# EFR32FG22C121F512GM32 register map
Vendor: Silicon Labs; Series: EFR32; File version: C
Registers are 32-bit, read-write, reset 0x0 unless marked. A register's access mark holds for its fields unless they carry their own. Offsets are from the block's base; [hi:lo] are bit positions; {n}, {i} and the like mark numbered series; 'fields as' and 'values as' point back to an identical list.

## CMU_S — CMU_S Registers
Base 0x40008000
Same registers: CMU_NS 0x50008000
0x00 IPVERSION ro reset 0x1
  [31:0] IPVERSION — IP Version ID
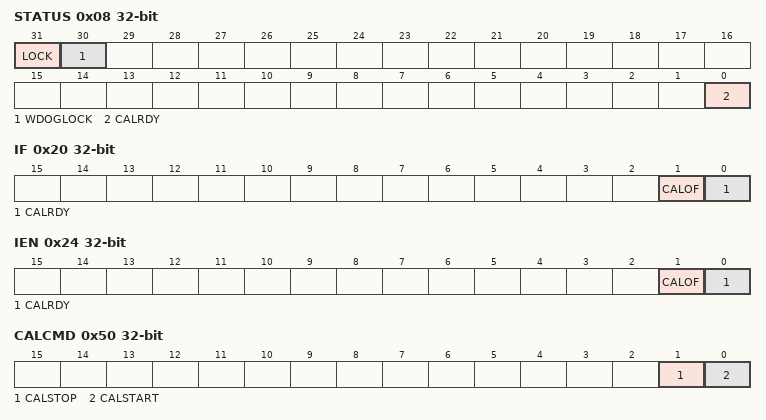
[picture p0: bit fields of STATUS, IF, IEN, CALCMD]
0x08 STATUS ro
  [31] LOCK — Configuration Lock Status
    0=UNLOCKED (Configuration lock is unlocked); 1=LOCKED (Configuration lock is locked)
  [30] WDOGLOCK — Configuration Lock Status for WDOG
    0=UNLOCKED (WDOG configuration lock is unlocked); 1=LOCKED (WDOG configuration lock is locked)
  [0] CALRDY — Calibration Ready
0x10 LOCK wo reset 0x93F7
  [15:0] LOCKKEY — Configuration Lock Key
    0x93F7=UNLOCK (Write this value to unlock)
0x14 WDOGLOCK wo reset 0x5257
  fields as LOCK
0x20 IF
  [1] CALOF — Calibration Overflow Interrupt Flag
  [0] CALRDY — Calibration Ready Interrupt Flag
0x24 IEN
  [1] CALOF — Calibration Overflow Interrupt Enable
  [0] CALRDY — Calibration Ready Interrupt Enable
0x50 CALCMD wo
  [1] CALSTOP — Calibration Stop
  [0] CALSTART — Calibration Start
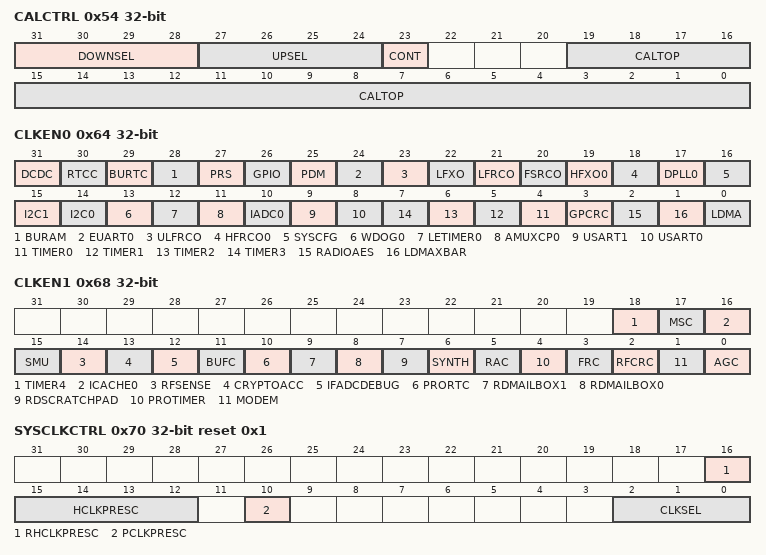
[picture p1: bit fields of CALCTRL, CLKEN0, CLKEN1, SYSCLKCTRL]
0x54 CALCTRL
  [31:28] DOWNSEL — Calibration Down-counter Select
    0=DISABLED (Down-counter is not clocked); 1=HCLK (HCLK is clocking down-counter); 2=PRS (PRS CMU_CALDN consumer is clocking down-counter); 3=HFXO (HFXO is clocking down-counter); 4=LFXO (LFXO is clocking down-counter); 5=HFRCODPLL (HFRCODPLL is clocking down-counter); 9=FSRCO (FSRCO is clocking down-counter); 10=LFRCO (LFRCO is clocking down-counter); 11=ULFRCO (ULFRCO is clocking down-counter)
  [27:24] UPSEL — Calibration Up-counter Select
    0=DISABLED (Up-counter is not clocked); 1=PRS (PRS CMU_CALUP consumer is clocking up-counter); 2=HFXO (HFXO is clocking up-counter); 3=LFXO (LFXO is clocking up-counter); 4=HFRCODPLL (HFRCODPLL is clocking up-counter); 8=FSRCO (FSRCO is clocking up-counter); 9=LFRCO (LFRCO is clocking up-counter); 10=ULFRCO (ULFRCO is clocking up-counter)
  [23] CONT — Continuous Calibration
  [19:0] CALTOP — Calibration Counter Top Value
0x58 CALCNT ro
  [19:0] CALCNT — Calibration Result Counter Value
0x64 CLKEN0
  [31] DCDC — Enable Bus Clock
  [30] RTCC — Enable Bus Clock
  [29] BURTC — Enable Bus Clock
  [28] BURAM — Enable Bus Clock
  [27] PRS — Enable Bus Clock
  [26] GPIO — Enable Bus Clock
  [25] PDM — Enable Bus Clock
  [24] EUART0 — Enable Bus Clock
  [23] ULFRCO — Enable Bus Clock
  [22] LFXO — Enable Bus Clock
  [21] LFRCO — Enable Bus Clock
  [20] FSRCO — Enable Bus Clock
  [19] HFXO0 — Enable Bus Clock
  [18] HFRCO0 — Enable Bus Clock
  [17] DPLL0 — Enable Bus Clock
  [16] SYSCFG — Enable Bus Clock
  [15] I2C1 — Enable Bus Clock
  [14] I2C0 — Enable Bus Clock
  [13] WDOG0 — Enable Bus Clock
  [12] LETIMER0 — Enable Bus Clock
  [11] AMUXCP0 — Enable Bus Clock
  [10] IADC0 — Enable Bus Clock
  [9] USART1 — Enable Bus Clock
  [8] USART0 — Enable Bus Clock
  [n+4] TIMER{n} (n=0..3) — Enable Bus Clock
  [3] GPCRC — Enable Bus Clock
  [2] RADIOAES — Enable Bus Clock
  [1] LDMAXBAR — Enable Bus Clock
  [0] LDMA — Enable Bus Clock
0x68 CLKEN1
  [18] TIMER4 — Enable Bus Clock
  [17] MSC — Enable Bus Clock
  [16] ICACHE0 — Enable Bus Clock
  [15] SMU — Enable Bus Clock
  [14] RFSENSE — Enable Bus Clock
  [13] CRYPTOACC — Enable Bus Clock
  [12] IFADCDEBUG — Enable Bus Clock
  [11] BUFC — Enable Bus Clock
  [10] PRORTC — Enable Bus Clock
  [9] RDMAILBOX1 — Enable Bus Clock
  [8] RDMAILBOX0 — Enable Bus Clock
  [7] RDSCRATCHPAD — Enable Bus Clock
  [6] SYNTH — Enable Bus Clock
  [5] RAC — Enable Bus Clock
  [4] PROTIMER — Enable Bus Clock
  [3] FRC — Enable Bus Clock
  [2] RFCRC — Enable Bus Clock
  [1] MODEM — Enable Bus Clock
  [0] AGC — Enable Bus Clock
0x70 SYSCLKCTRL reset 0x1
  [16] RHCLKPRESC — Radio HCLK Prescaler
    0=DIV1 (Radio HCLK is SYSCLK divided by 1); 1=DIV2 (Radio HCLK is SYSCLK divided by 2)
  [15:12] HCLKPRESC — HCLK Prescaler
    0=DIV1 (HCLK is SYSCLK divided by 1); 1=DIV2 (HCLK is SYSCLK divided by 2); 3=DIV4 (HCLK is SYSCLK divided by 4); 7=DIV8 (HCLK is SYSCLK divided by 8); 15=DIV16 (HCLK is SYSCLK divided by 16)
  [10] PCLKPRESC — PCLK Prescaler
    0=DIV1 (PCLK is HCLK divided by 1); 1=DIV2 (PCLK is HCLK divided by 2)
  [2:0] CLKSEL — Clock Select
    1=FSRCO (FSRCO is clocking SYSCLK); 2=HFRCODPLL (HFRCODPLL is clocking SYSCLK); 3=HFXO (HFXO is clocking SYSCLK); 4=CLKIN0 (CLKIN0 is clocking SYSCLK)
0x80 TRACECLKCTRL
  [5:4] PRESC — TRACECLK Prescaler
    0=DIV1 (TRACECLK is SYSCLK divided by 1); 1=DIV2 (TRACECLK is SYSCLK divided by 2); 3=DIV4 (TRACECLK is SYSCLK divided by 4)
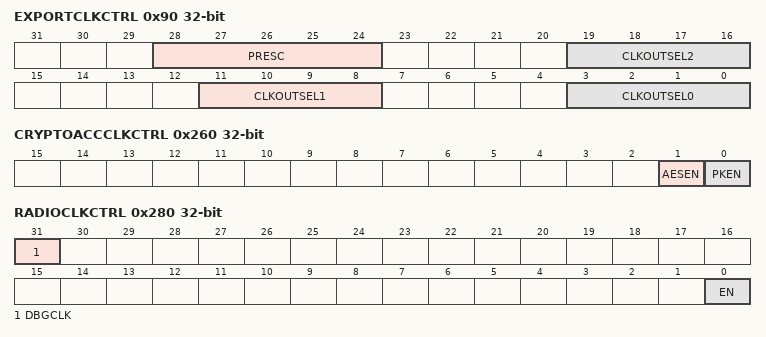
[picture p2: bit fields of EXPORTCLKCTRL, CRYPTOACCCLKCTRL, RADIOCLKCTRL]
0x90 EXPORTCLKCTRL
  [28:24] PRESC — EXPORTCLK Prescaler
  [19:16] CLKOUTSEL2 — Clock Output Select 2
    0=DISABLED (CLKOUT2 is not clocked); 1=HCLK (HCLK is clocking CLKOUT2); 2=HFEXPCLK (EXPORTCLK is clocking CLKOUT2); 3=ULFRCO (ULFRCO is clocking CLKOUT2); 4=LFRCO (LFRCO is clocking CLKOUT2); 5=LFXO (LFXO is clocking CLKOUT2); 6=HFRCODPLL (HFRCODPLL is clocking CLKOUT2); 7=HFXO (HFXO is clocking CLKOUT2); 8=FSRCO (FSRCO is clocking CLKOUT2)
  [11:8] CLKOUTSEL1 — Clock Output Select 1
    0=DISABLED (CLKOUT1 is not clocked); 1=HCLK (HCLK is clocking CLKOUT1); 2=HFEXPCLK (EXPORTCLK is clocking CLKOUT1); 3=ULFRCO (ULFRCO is clocking CLKOUT1); 4=LFRCO (LFRCO is clocking CLKOUT1); 5=LFXO (LFXO is clocking CLKOUT1); 6=HFRCODPLL (HFRCODPLL is clocking CLKOUT1); 7=HFXO (HFXO is clocking CLKOUT1); 8=FSRCO (FSRCO is clocking CLKOUT1)
  [3:0] CLKOUTSEL0 — Clock Output Select 0
    0=DISABLED (CLKOUT0 is not clocked); 1=HCLK (HCLK is clocking CLKOUT0); 2=HFEXPCLK (EXPORTCLK is clocking CLKOUT0); 3=ULFRCO (ULFRCO is clocking CLKOUT0); 4=LFRCO (LFRCO is clocking CLKOUT0); 5=LFXO (LFXO is clocking CLKOUT0); 6=HFRCODPLL (HFRCODPLL is clocking CLKOUT0); 7=HFXO (HFXO is clocking CLKOUT0); 8=FSRCO (FSRCO is clocking CLKOUT0)
0x100 DPLLREFCLKCTRL
  [1:0] CLKSEL — Clock Select
    0=DISABLED (DPLLREFCLK is not clocked); 1=HFXO (HFXO is clocking DPLLREFCLK); 2=LFXO (LFXO is clocking DPLLREFCLK); 3=CLKIN0 (CLKIN0 is clocking DPLLREFCLK)
0x120 EM01GRPACLKCTRL reset 0x1
  [1:0] CLKSEL — Clock Select
    1=HFRCODPLL (HFRCODPLL is clocking EM01GRPACLK); 2=HFXO (HFXO is clocking EM01GRPACLK); 3=FSRCO (FSRCO is clocking EM01GRPACLK)
0x124 EM01GRPBCLKCTRL reset 0x1
  [2:0] CLKSEL — Clock Select
    1=HFRCODPLL (HFRCODPLL is clocking EM01GRPBCLK); 2=HFXO (HFXO is clocking EM01GRPBCLK); 3=FSRCO (FSRCO is clocking EM01GRPBCLK); 4=CLKIN0 (CLKIN0 is clocking EM01GRPBCLK); 5=HFRCODPLLRT (HFRCODPLL (re-timed) is clocking EM01GRPBCLK); 6=HFXORT (HFXO (re-timed) is clocking EM01GRPBCLK)
0x140 EM23GRPACLKCTRL reset 0x1
  [1:0] CLKSEL — Clock Select
    1=LFRCO (LFRCO is clocking EM23GRPACLK); 2=LFXO (LFXO is clocking EM23GRPACLK); 3=ULFRCO (ULFRCO is clocking EM23GRPACLK)
0x160 EM4GRPACLKCTRL reset 0x1
  [1:0] CLKSEL — Clock Select
    1=LFRCO (LFRCO is clocking EM4GRPACLK); 2=LFXO (LFXO is clocking EM4GRPACLK); 3=ULFRCO (ULFRCO is clocking EM4GRPACLK)
0x180 IADCCLKCTRL reset 0x1
  [1:0] CLKSEL — Clock Select
    1=EM01GRPACLK (EM01GRPACLK is clocking IADCCLK); 2=FSRCO (FSRCO is clocking IADCCLK)
0x200 WDOG0CLKCTRL reset 0x1
  [2:0] CLKSEL — Clock Select
    1=LFRCO (LFRCO is clocking WDOG0CLK); 2=LFXO (LFXO is clocking WDOG0CLK); 3=ULFRCO (ULFRCO is clocking WDOG0CLK); 4=HCLKDIV1024 (HCLKDIV1024 is clocking WDOG0CLK)
0x220 EUART0CLKCTRL reset 0x1
  [1:0] CLKSEL — Clock Select
    0=DISABLED (UART is not clocked); 1=EM01GRPACLK (EM01GRPACLK is clocking UART); 2=EM23GRPACLK (EM23GRPACLK is clocking UART)
0x240 RTCCCLKCTRL reset 0x1
  [1:0] CLKSEL — Clock Select
    1=LFRCO (LFRCO is clocking RTCCCLK); 2=LFXO (LFXO is clocking RTCCCLK); 3=ULFRCO (ULFRCO is clocking RTCCCLK)
0x248 PRORTCCLKCTRL reset 0x1
  [1:0] CLKSEL — Clock Select
    1=LFRCO (LFRCO is clocking PRORTCCLK); 2=LFXO (LFXO is clocking PRORTCCLK); 3=ULFRCO (ULFRCO is clocking PRORTCCLK)
0x260 CRYPTOACCCLKCTRL
  [1] AESEN — AES Enable
  [0] PKEN — PK Enable
0x280 RADIOCLKCTRL
  [31] DBGCLK — Enable Clock for Debugger
  [0] EN — Enable
